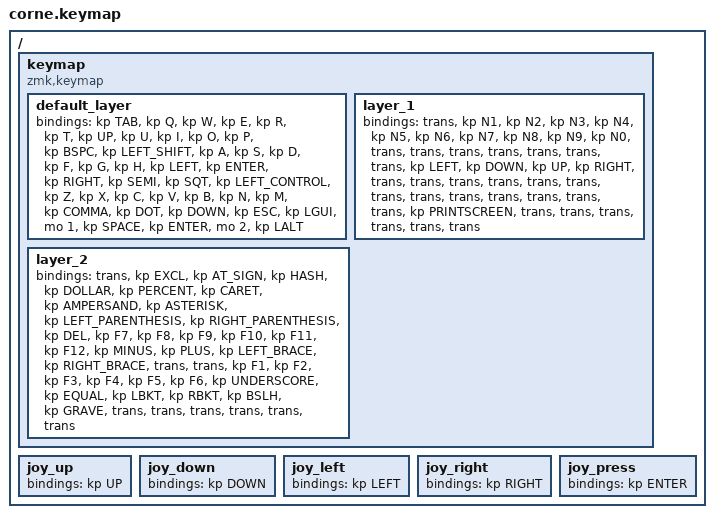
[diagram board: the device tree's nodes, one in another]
/*
 * Copyright (c) 2020 The ZMK Contributors
 *
 * SPDX-License-Identifier: MIT
 */

#include <behaviors.dtsi>
#include <dt-bindings/zmk/keys.h>

/ {
    keymap {
        compatible = "zmk,keymap";

        default_layer {
            // -----------------------------------------------------------------------------------------
            // |  TAB |  Q  |  W  |  E  |  R  |  T  |   |  Y  |  U  |  I  |  O  |  P  | BSPC |
            // | CTRL |  A  |  S  |  D  |  F  |  G  |   |  H  |  J  |  K  |  L  |  ;  |  '   |
            // | SHFT |  Z  |  X  |  C  |  V  |  B  |   |  N  |  M  |  ,  |  .  |  /  | ESC  |
            //                    | GUI | LWR | SPC |   | LALT | RSE  | ENT |

            bindings = <
&kp TAB  &kp Q  &kp W  &kp E  &kp R  &kp T  &kp UP  &kp U  &kp I  &kp O  &kp P  &kp BSPC  &kp LEFT_SHIFT  &kp A  &kp S  &kp D  &kp F  &kp G  &kp H  &kp LEFT  &kp ENTER  &kp RIGHT  &kp SEMI  &kp SQT  &kp LEFT_CONTROL  &kp Z  &kp X  &kp C  &kp V  &kp B  &kp N  &kp M  &kp COMMA  &kp DOT  &kp DOWN  &kp ESC  &kp LGUI  &mo 1  &kp SPACE  &kp ENTER  &mo 2  &kp LALT
            >;
        };

        layer_1 {
            // -----------------------------------------------------------------------------------------
            // |  TAB |  1  |  2  |  3  |  4  |  5  |   |  6  |  7  |  8  |  9  |  0  | BSPC |
            // | BTCLR| BT1 | BT2 | BT3 | BT4 | BT5 |   | LFT | DWN |  UP | RGT |     |      |
            // | SHFT | power |     |     |     |     |   |     |     |     |     |     |      |
            //                    |     |     |     |   |     |     |     |

            bindings = <
&trans  &kp N1  &kp N2  &kp N3  &kp N4  &kp N5  &kp N6  &kp N7  &kp N8  &kp N9  &kp N0  &trans  &trans  &trans  &trans  &trans  &trans  &trans  &kp LEFT  &kp DOWN  &kp UP  &kp RIGHT  &trans  &trans  &trans  &trans  &trans  &trans  &trans  &trans  &trans  &trans  &trans  &trans  &trans  &kp PRINTSCREEN  &trans  &trans  &trans  &trans  &trans  &trans
            >;
        };

        layer_2 {
            // -----------------------------------------------------------------------------------------
            // |  TAB |  !  |  @  |  #  |  $  |  %  |   |  ^  |  &  |  *  |  (  |  )  | BSPC |
            // | CTRL |     |     |     |     |     |   |  -  |  =  |  [  |  ]  |  \  |  `   |
            // | SHFT |     |     |     |     |     |   |  _  |  +  |  {  |  }  | "|" |  ~   |
            //                    |     |     |     |   |     |     |     |

            bindings = <
&trans  &kp EXCL  &kp AT_SIGN  &kp HASH  &kp DOLLAR  &kp PERCENT  &kp CARET  &kp AMPERSAND  &kp ASTERISK  &kp LEFT_PARENTHESIS  &kp RIGHT_PARENTHESIS  &kp DEL  &kp F7  &kp F8  &kp F9  &kp F10  &kp F11  &kp F12  &kp MINUS  &kp PLUS  &kp LEFT_BRACE  &kp RIGHT_BRACE  &trans  &trans  &kp F1  &kp F2  &kp F3  &kp F4  &kp F5  &kp F6  &kp UNDERSCORE  &kp EQUAL  &kp LBKT  &kp RBKT  &kp BSLH  &kp GRAVE  &trans  &trans  &trans  &trans  &trans  &trans
            >;
        };
    };

    joy_up    { bindings = <&kp UP>; };
    joy_down  { bindings = <&kp DOWN>; };
    joy_left  { bindings = <&kp LEFT>; };
    joy_right { bindings = <&kp RIGHT>; };
    joy_press { bindings = <&kp ENTER>; };

};
